VERSION ""

NS_ :

BS_:

BU_: ECU KB IPC

BO_ 278 IPCLights: 8 ECU

BO_ 277 TurnSignals: 8 KB
 SG_ Turn_Sig_R : 1|1@1+ (1,0) [0|1] "1"  IPC
 SG_ Turn_Sig_L : 0|1@1+ (1,0) [0|1] "bool"  IPC

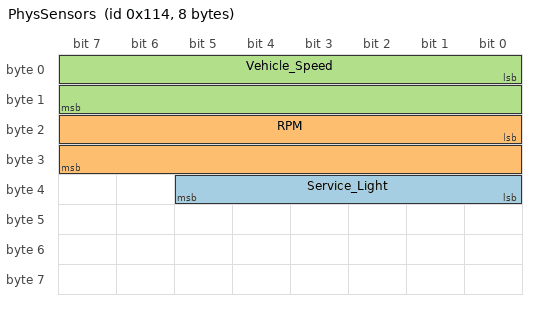
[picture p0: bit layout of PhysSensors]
BO_ 276 PhysSensors: 8 ECU
 SG_ Service_Light : 32|6@1+ (1,0) [0|127] ""  IPC
 SG_ RPM : 16|16@1+ (1,0) [0|8000] "RPM"  IPC
 SG_ Vehicle_Speed : 0|16@1+ (1,0) [0|260] "kph"  IPC

BO_ 275 Steering: 8 KB
 SG_ Steer_R : 1|1@1+ (1,0) [0|1] "bool" Vector__XXX
 SG_ Steer_L : 0|1@1+ (1,0) [0|1] "bool" Vector__XXX

BO_ 274 AcceleratorBrake: 8 KB
 SG_ Brake : 1|1@1+ (1,0) [0|1] "bool"  IPC
 SG_ Accelerator : 0|1@1+ (1,0) [0|1] "bool"  IPC

BA_DEF_  "BusType" STRING ;
BA_DEF_DEF_  "BusType" "CAN";
